# ipro7 register map
Vendor: intelpro; Series: BTBLE
CPU: ipro7, little endian
Registers are 32-bit, read-write, reset 0x0 unless marked. A register's access mark holds for its fields unless they carry their own. Offsets are from the block's base; [hi:lo] are bit positions; {n}, {i} and the like mark numbered series.

## GLB
Base 0x30000000
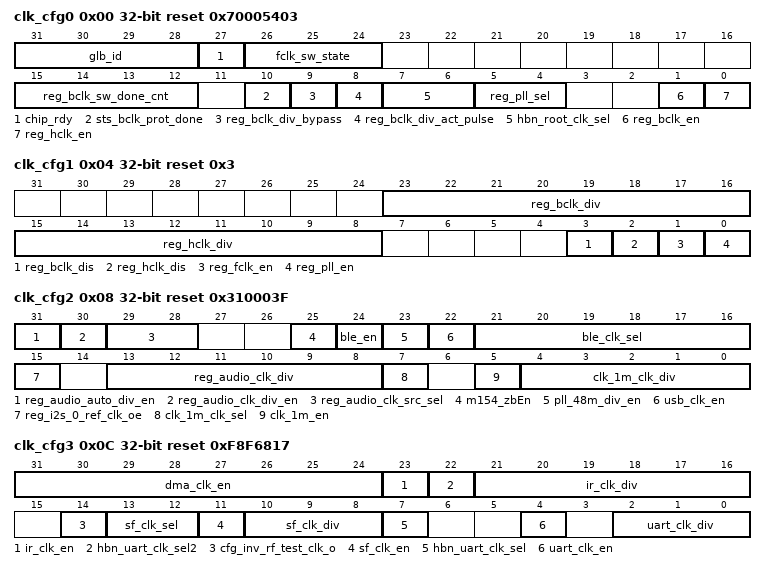
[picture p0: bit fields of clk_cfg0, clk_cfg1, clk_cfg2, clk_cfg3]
0x00 clk_cfg0 reset 0x70005403 (reset mask 0xFFFB3F)
  [31:28] glb_id ro
  [27] chip_rdy ro
  [26:24] fclk_sw_state ro
  [15:12] reg_bclk_sw_done_cnt — BCLK division protection done counter
  [10] sts_bclk_prot_done ro — clk protection done
  [9] reg_bclk_div_bypass — BCLK division protection bypass
  [8] reg_bclk_div_act_pulse wo — BCLK division protection activation
  [7:6] hbn_root_clk_sel ro — root clock selection from HBN (0: RC32M 1: XTAL 2/3: PLL others)
  [5:4] reg_pll_sel — pll clock selection 0: 25.6MHz 1: 42.66MHz 2: 64MHz 3: 128MHz
  [1] reg_bclk_en — bclk force on
  [0] reg_hclk_en — hclk force on
0x04 clk_cfg1 reset 0x3
  [23:16] reg_bclk_div — bclk divide from hclk
  [15:8] reg_hclk_div — hclk divide from root clock (clock source selected by hbn_root_clk_sel)
  [3] reg_bclk_dis — bclk force disable
  [2] reg_hclk_dis — hclk force disable
  [1] reg_fclk_en — fclk force on
  [0] reg_pll_en — pll clock enable for fclk
0x08 clk_cfg2 reset 0x310003F
  [31] reg_audio_auto_div_en — Audio auto div enable
  [30] reg_audio_clk_div_en — Audio clock div enable
  [29:28] reg_audio_clk_src_sel — 0 : 2.032MHz(128/63 from DLL), 1: 6.095MHz(128/21 from DLL), 2:pll_48m_clk, 3.clkpll_postdiv_outclk
  [25] m154_zbEn — mac154 zigbee clock enable
  [24] ble_en — ble clock enable
  [23] pll_48m_div_en — USB Clock div2 from 96MHz
  [22] usb_clk_en — USB Clock Enable
  [21:16] ble_clk_sel — HW reserved ; for ble to generate 1us/0.5us tick pulse
  [15] reg_i2s_0_ref_clk_oe — 0 : no output reference clock on I2S_0 ref_clock port ; 1: output reference clock on I2S_0 ref_clock port
  [13:8] reg_audio_clk_div — Audio clock div
  [7] clk_1m_clk_sel — KEY Clock Source Select. 0:xclk 1:f32k (PDS mode)
  [5] clk_1m_en — Clock 1M enable for kys/qdec
  [4:0] clk_1m_clk_div — KEY Clock Divider qdec_clk_sel/(N+1), default 1MHz
0x0C clk_cfg3 reset 0xF8F6817 (reset mask 0xFFBFFF7F)
  [31:24] dma_clk_en — DMA CH0~7 Clock Enable ; config all 0 if disable DMA
  [23] ir_clk_en — IR remote Clock Enable
  [22] hbn_uart_clk_sel2 ro — UART clock selection2 from HBN (0 : result of hbn_uart_clk_sel (fclk or dll_div2(64MHz)) 1: XCLK (XTAL or RC32M))
  [21:16] ir_clk_div — IR remote Clock Divider xclk(N+1)
  [14] cfg_inv_rf_test_clk_o — 1: invert rf_test_clk out, 0 : no change
  [13:12] sf_clk_sel — Flash Clock Select 0: xclk 1: dll_div2(64Mhz) 2: bclk (Default) 3: pll_80m_clk (80MHz)
  [11] sf_clk_en — Flash Clock Enable
  [10:8] sf_clk_div — Flash Clock Divider (Selected Flash Clock)/(N+1)
  [7] hbn_uart_clk_sel ro — UART clock selection from HBN (0:fclk 1:dll_div2(64MHz))
  [4] uart_clk_en — UART Clock Enable
  [2:0] uart_clk_div — UART Clock Divider hbn_uart_clk_sel/(N+1)
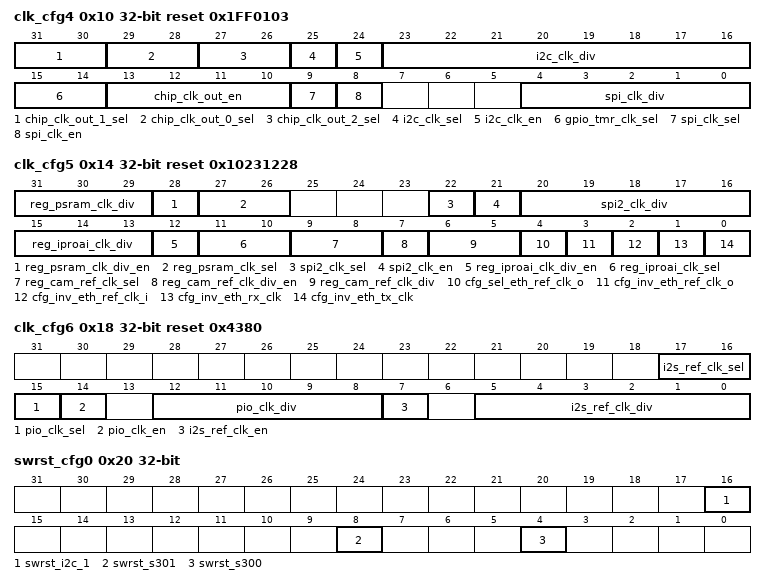
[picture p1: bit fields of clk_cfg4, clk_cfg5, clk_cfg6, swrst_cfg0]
0x10 clk_cfg4 reset 0x1FF0103
  [31:30] chip_clk_out_1_sel — clk_out_1 selection & clk_out_3 selection (0: no chip clock out, 1: f32k_clk, 2: ana_xtal_clk, 3: dig_xtal_clk)
  [29:28] chip_clk_out_0_sel — clk_out_0 selection & clk_out_2 selection (0: no chip clock out, 1: dll_div63, 2: dll_div21, 3: xclk)
  [27:26] chip_clk_out_2_sel — clk_out_1 selection & clk_out_3 selection (0: no chip clock out, 1: i2s_ref_clk, 2: pll_48m_clk, 3: clkpll_postdiv_outclk)
  [25] i2c_clk_sel — 0: BCLK, 1: XCLK
  [24] i2c_clk_en — I2C Master Clock Out Enable
  [23:16] i2c_clk_div — I2C Master Clock Out Divider (Freq_of_BCLK/(N+1))
  [15:14] gpio_tmr_clk_sel — select GPIO Clock Input From GPIO Function 0: 0: chip_clk_inout[0] 1: chip_clk_inout[1] 2: chip_clk_inout[2] 3: chip_clk_inout[3]
  [13:10] chip_clk_out_en — chip_clk_out enable for chip_clk_inout[3:0]
  [9] spi_clk_sel — 0: BCLK, 1: XCLK
  [8] spi_clk_en — SPI Clock Enable (Default : Enable)
  [4:0] spi_clk_div — SPI Clock Divider (BUS_CLK/(N+1)), default BUS_CLK/4
0x14 clk_cfg5 reset 0x10231228
  [31:29] reg_psram_clk_div — psram clock divide cnt
  [28] reg_psram_clk_div_en — psram clock enable
  [27:26] reg_psram_clk_sel — psram clock source selection 2'd0 - bclk 2'd1 - pll_160m_clk 2'd2 - pll_480m_clk 2'd3 - pll_192m_clk
  [22] spi2_clk_sel — 0: BCLK, 1: XCLK
  [21] spi2_clk_en — SPI Clock Enable (Default : Enable)
  [20:16] spi2_clk_div — SPI Clock Divider (BUS_CLK/(N+1)), default BUS_CLK/4
  [15:13] reg_iproai_clk_div — IPROAI clock divide cnt
  [12] reg_iproai_clk_div_en — IPROAI clock enable
  [11:10] reg_iproai_clk_sel — IPROAI clock source selection 2'd0 - bclk 2'd1 - pll_320m_clk 2'd2 - pll_240m_clk 2'd3 - dll_div5
  [9:8] reg_cam_ref_clk_sel — 2'd0 - xclk 2'd1 - dll_div3 2'd2 - pll_48m_clk 2'd3 - clkpll_postdiv_outclk
  [7] reg_cam_ref_clk_div_en — camera clock enable
  [6:5] reg_cam_ref_clk_div — camera clock divider cnt
  [4] cfg_sel_eth_ref_clk_o — 0 : select outside 50MHz RMII ref clock, 1: select inside 50MHz RMII ref clock
  [3] cfg_inv_eth_ref_clk_o — if cfg_sel_eth_ref_clk_o = 1, set this bit to 1 will invert the clock to RMII PHY
  [2] cfg_inv_eth_ref_clk_i — Invert clock to RMII REF_CLK
  [1] cfg_inv_eth_rx_clk — Invert clock to our RMII MAC RX
  [0] cfg_inv_eth_tx_clk — Invert clock to our RMII MAC TX
0x18 clk_cfg6 reset 0x4380
  [17:16] i2s_ref_clk_sel — 0 : 2.032MHz(128/63 from DLL), 1: 6.095MHz(128/21 from DLL), 2:pll_48m_clk, 3.clkpll_postdiv_outclk
  [15] pio_clk_sel — 0: PLL_160M_CLK, 1: XCLK
  [14] pio_clk_en — PIO Clock Enable (Default : Enable)
  [12:8] pio_clk_div — PIO Clock Divider (BUS_CLK/(N+1)), default BUS_CLK/4
  [7] i2s_ref_clk_en — I2S Clock Enable
  [5:0] i2s_ref_clk_div — I2S Clock Divider(N+1)
0x20 swrst_cfg0
  [16] swrst_i2c_1
  [8] swrst_s301 — BLE
  [4] swrst_s300 — M154
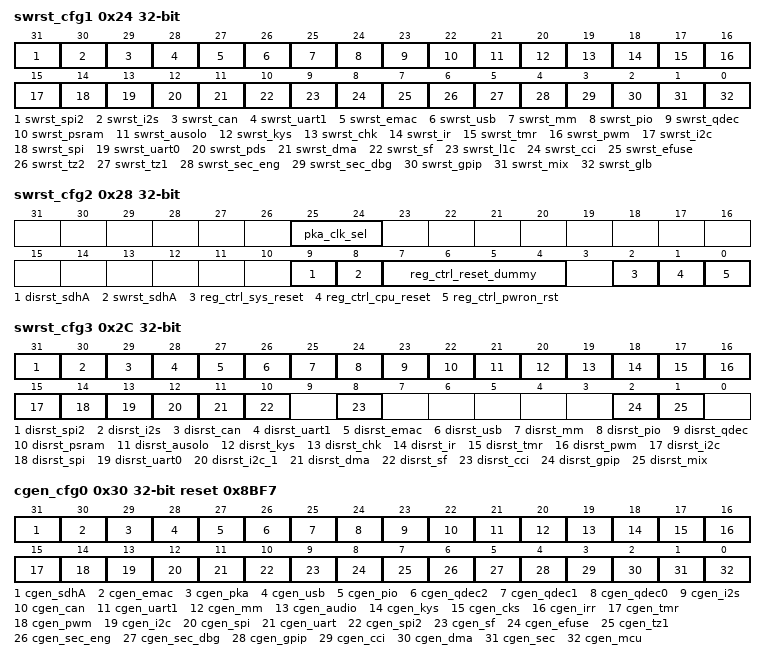
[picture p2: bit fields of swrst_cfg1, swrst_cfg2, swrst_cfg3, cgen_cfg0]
0x24 swrst_cfg1
  [31] swrst_spi2, [30] swrst_i2s, [29] swrst_can, [28] swrst_uart1, [27] swrst_emac, [26] swrst_usb, [25] swrst_mm, [24] swrst_pio, [23] swrst_qdec, [22] swrst_psram, [21] swrst_ausolo, [20] swrst_kys, [19] swrst_chk, [18] swrst_ir, [17] swrst_tmr, [16] swrst_pwm, [15] swrst_i2c, [14] swrst_spi, [13] swrst_uart0, [12] swrst_pds, [11] swrst_dma, [10] swrst_sf, [9] swrst_l1c, [8] swrst_cci, [7] swrst_efuse, [6] swrst_tz2, [5] swrst_tz1, [4] swrst_sec_eng, [3] swrst_sec_dbg, [2] swrst_gpip, [1] swrst_mix, [0] swrst_glb
0x28 swrst_cfg2
  [25:24] pka_clk_sel — 0:96Mhz, 1:128MHz, 2: 64MHz, 3: 42.6MHz
  [9] disrst_sdhA
  [8] swrst_sdhA
  [7:4] reg_ctrl_reset_dummy
  [2] reg_ctrl_sys_reset
  [1] reg_ctrl_cpu_reset
  [0] reg_ctrl_pwron_rst
0x2C swrst_cfg3
  [31] disrst_spi2, [30] disrst_i2s, [29] disrst_can, [28] disrst_uart1, [27] disrst_emac, [26] disrst_usb, [25] disrst_mm, [24] disrst_pio, [23] disrst_qdec, [22] disrst_psram, [21] disrst_ausolo, [20] disrst_kys, [19] disrst_chk, [18] disrst_ir, [17] disrst_tmr, [16] disrst_pwm, [15] disrst_i2c, [14] disrst_spi, [13] disrst_uart0, [12] disrst_i2c_1, [11] disrst_dma, [10] disrst_sf, [8] disrst_cci, [2] disrst_gpip, [1] disrst_mix
0x30 cgen_cfg0 reset 0x8BF7
  [31] cgen_sdhA, [30] cgen_emac, [29] cgen_pka, [28] cgen_usb, [27] cgen_pio, [26] cgen_qdec2, [25] cgen_qdec1, [24] cgen_qdec0, [23] cgen_i2s, [22] cgen_can, [21] cgen_uart1, [20] cgen_mm, [19] cgen_audio, [18] cgen_kys, [17] cgen_cks, [16] cgen_irr, [15] cgen_tmr, [14] cgen_pwm, [13] cgen_i2c, [12] cgen_spi, [11] cgen_uart, [10] cgen_spi2, [9] cgen_sf, [8] cgen_efuse, [7] cgen_tz1, [6] cgen_sec_eng, [5] cgen_sec_dbg, [4] cgen_gpip, [3] cgen_cci, [2] cgen_dma, [1] cgen_sec, [0] cgen_mcu
0x34 cgen_cfg1
  [14] cgen_i2c_1
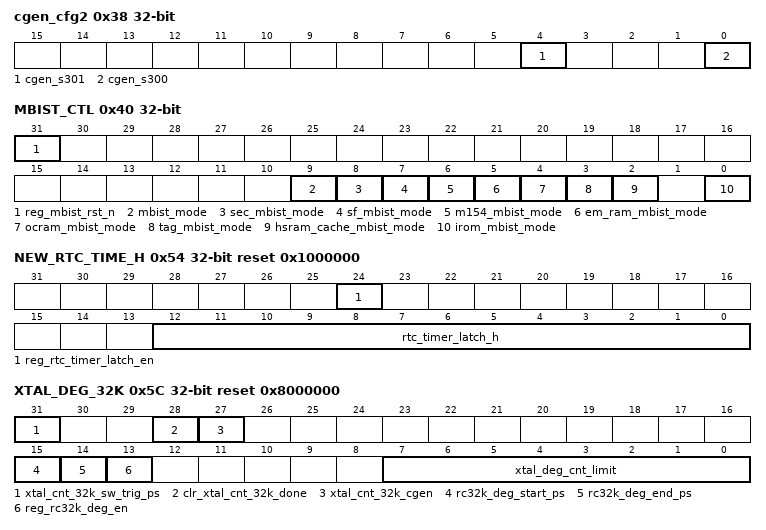
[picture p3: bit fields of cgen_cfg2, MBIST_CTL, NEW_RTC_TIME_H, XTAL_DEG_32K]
0x38 cgen_cfg2
  [4] cgen_s301 — ble clock enable (ble_en should also be 1)
  [0] cgen_s300 — mac154 zigbee clock enable (m154_zbEn should also be 1)
0x40 MBIST_CTL
  [31] reg_mbist_rst_n — MBIST Reset
  [9] mbist_mode — PIN MUX MBIST Mode
  [8] sec_mbist_mode
  [7] sf_mbist_mode
  [6] m154_mbist_mode
  [5] em_ram_mbist_mode — EM RAM MBIST Mode (16KB)
  [4] ocram_mbist_mode — OCRAM MBIST Mode (48KB)
  [3] tag_mbist_mode
  [2] hsram_cache_mbist_mode — HSRAM_CACHE MBIST Mode (16KB)
  [0] irom_mbist_mode
0x44 MBIST_STAT
0x50 NEW_RTC_TIME_L reset not defined
  [31:0] rtc_timer_latch_l ro — RTC time latched value bit 31:0
0x54 NEW_RTC_TIME_H reset 0x1000000 (reset mask 0xFFFFE000)
  [24] reg_rtc_timer_latch_en — Enable RTC Timer Latch, need to wait about 15us for 1st timer read, and no need to wait for next read
  [12:0] rtc_timer_latch_h ro — RTC time latched value bit 44:32
0x5C XTAL_DEG_32K reset 0x8000000
  [31] xtal_cnt_32k_sw_trig_ps wo — write one to set xtal_cnt_32k_process (0x4000E04C[29])
  [28] clr_xtal_cnt_32k_done wo — write one to clear xtal_cnt_32k_done (0x4000E04C[30])
  [27] xtal_cnt_32k_cgen
  [15] rc32k_deg_start_ps wo
  [14] rc32k_deg_end_ps wo
  [13] reg_rc32k_deg_en
  [7:0] xtal_deg_cnt_limit
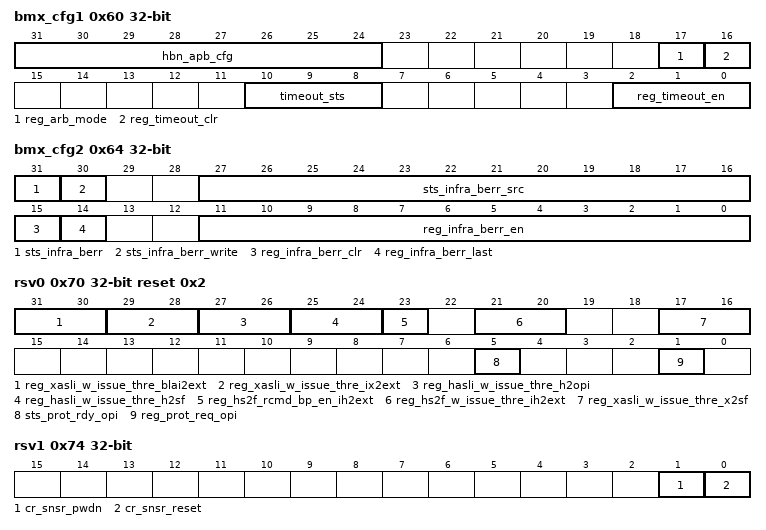
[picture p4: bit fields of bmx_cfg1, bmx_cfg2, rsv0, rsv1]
0x60 bmx_cfg1 (reset mask 0xFFFFF8FF)
  [31:24] hbn_apb_cfg — HW reserved. [7] hbn_hold_en [6:4] hbn_hold_cycle [3] hbn_setup_en [2:0] hbn_setup_cycle
  [17] reg_arb_mode — Bus arbiter: 0:fix, 2:round-robin, 3:random
  [16] reg_timeout_clr — Timeout Clear
  [10:8] timeout_sts ro — Bus timeout status
  [2:0] reg_timeout_en — Bus timeout enable: detect slave no reaponse in 1024 cycles
0x64 bmx_cfg2 (reset mask 0x3000FFFF)
  [31] sts_infra_berr ro — Bus addr error status
  [30] sts_infra_berr_write ro — Bus addr error write/read
  [27:16] sts_infra_berr_src ro — Bus addr error source
  [15] reg_infra_berr_clr — Bus addr error clear
  [14] reg_infra_berr_last — Bus addr error latch last addr
  [11:0] reg_infra_berr_en — Bus addr error monitor enable
0x68 bmx_err_addr reset not defined
  [31:0] sts_infra_berr_addr ro — Bus error addr (the first one)
0x6C bmx_cfg3
  [31:0] reg_frun_pclk — APB clock freerun
0x70 rsv0 reset 0x2 (reset mask 0xFFFFFFDF)
  [31:30] reg_xasli_w_issue_thre_blai2ext, [29:28] reg_xasli_w_issue_thre_ix2ext, [27:26] reg_hasli_w_issue_thre_h2opi, [25:24] reg_hasli_w_issue_thre_h2sf, [23] reg_hs2f_rcmd_bp_en_ih2ext, [21:20] reg_hs2f_w_issue_thre_ih2ext, [17:16] reg_xasli_w_issue_thre_x2sf, [5] sts_prot_rdy_opi ro, [1] reg_prot_req_opi
0x74 rsv1
  [1] cr_snsr_pwdn, [0] cr_snsr_reset
0x78 rsv2
0x7C rsv3 reset 0xFFFFFFFF
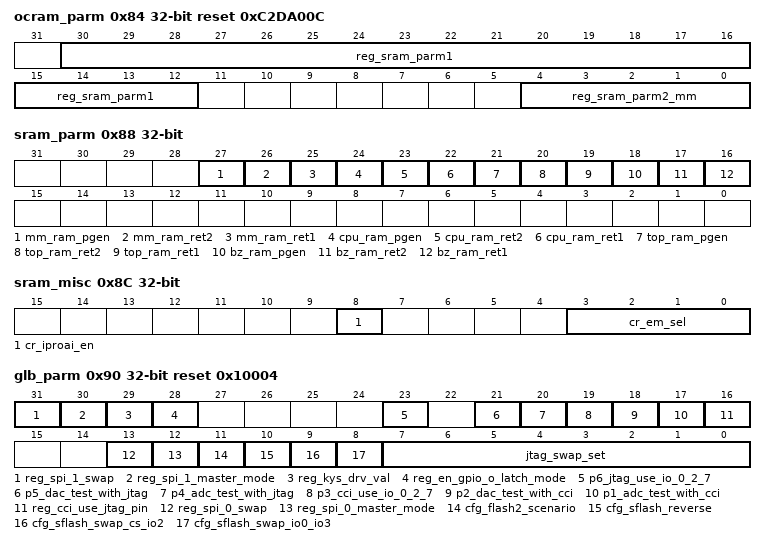
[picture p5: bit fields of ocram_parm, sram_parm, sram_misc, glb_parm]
0x84 ocram_parm reset 0xC2DA00C
  [30:12] reg_sram_parm1 — [30:29]=ram_bus[27:26]=WABLM_SRAM [28:26]=ram_bus[25:23]=EMA_SRAM [25:24]=ram_bus[22:21]=WABLM_RF [23:22]=ram_bus[20:19]=RAWLM [21]=ram_bus[18]=WABL [20]=ram_bus[17]=RAWL [19:18]=ram_bus[16:15]=EMAW [17:15]=ram_bus[14:12]=EMA_RF [14:12]=ram_bus[11:9]=EMA_ROM
  [4:0] reg_sram_parm2_mm — [5]=ram_bus[32]=DVSE [4:0]=ram_bus[31:28]=DVS
0x88 sram_parm
  [27] mm_ram_pgen, [26] mm_ram_ret2, [25] mm_ram_ret1, [24] cpu_ram_pgen, [23] cpu_ram_ret2, [22] cpu_ram_ret1, [21] top_ram_pgen, [20] top_ram_ret2, [19] top_ram_ret1, [18] bz_ram_pgen, [17] bz_ram_ret2, [16] bz_ram_ret1
0x8C sram_misc
  [8] cr_iproai_en — IPROAI SRAM enable 1'b0 - IPROAI disable / OCRAM - 256KB 1'b1 - IPROAI enable / OCRAM - 128KB
  [3:0] cr_em_sel — 4'b0000 - EM 0KB 4'b1000 - EM 16KB 4'b1100 - EM 32KB 4'b1110 - EM 48KB 4'b1111 - EM 64KB
0x90 glb_parm reset 0x10004
  [31] reg_spi_1_swap — 1: SWAP SPI1 MOSI with MISO ; 0 No SWAP
  [30] reg_spi_1_master_mode — 1 : SPI_1 Pad Act as Master, 0: SPI_1 Pad Act as Slave
  [29] reg_kys_drv_val — 1: Active Key Scan Column Drive, 0: Disable Key Scan Column Drive
  [28] reg_en_gpio_o_latch_mode — 1 : Enable GPIO_O Latch Mode
  [23] p6_jtag_use_io_0_2_7 — GPIO Scenario, set this bit will force GPI0/1/2/7 to JTAG Function
  [21] p5_dac_test_with_jtag — GPIO Scenario, set this bit will lead all GPIO enter DACTest Mode with JTAG
  [20] p4_adc_test_with_jtag — GPIO Scenario, set this bit will lead all GPIO enter ADCTest Mode with JTAG
  [19] p3_cci_use_io_0_2_7 — GPIO Scenario, set this bit will force GPIO0/1/2/7 to CCI Function
  [18] p2_dac_test_with_cci — GPIO Scenario, set this bit will lead all GPIO enter DACTest Mode with CCI
  [17] p1_adc_test_with_cci — GPIO Scenario, set this bit will lead all GPIO enter ADCTest Mode with CCI
  [16] reg_cci_use_jtag_pin — 1: CCI USE GPIO0~2 @ JTAG Function
  [13] reg_spi_0_swap — 1: SWAP SPI0 MOSI with MISO ; 0 No SWAP
  [12] reg_spi_0_master_mode — 1 : SPI_0 Pad Act as Master, 0: SPI_0 Pad Act as Slave
  [11] cfg_flash2_scenario — 0 : Flash GPIO Scenario Disabled, Flash GPIO Function Set by SW 1 : Flash GPIO Scenario Enable , Force GPIO23~28 to Flash2 Function
  [10] cfg_sflash_reverse — 1 : Embedded Flash Interface Reverse 0 : no revserse
  [9] cfg_sflash_swap_cs_io2 — Embedded Flash SWAP 1 : SWAP SFLASH CS with IO2 : No SWAP SFLASH CS With IO2
  [8] cfg_sflash_swap_io0_io3 — 1 : SWAP SFLASH IO3 with IO 0 : No SWAP SFLASH IO3 With IO0
  [7:0] jtag_swap_set — [0] : SWAP JTAG GPIO SET0 (GPIO0~GPIO3) (1: E21_TMS/E21_TDI/E21_TCK/E21_TDO -> E21_TCK/E21_TDO/E21_TMS/E21_TDI) [1] : SWAP JTAG GPIO SET0 (GPIO4~GPIO7) (1: E21_TMS/E21_TDI/E21_TCK/E21_TDO -> E21_TCK/E21_TDO/E21_TMS/E21_TDI) [2] : SWAP JTAG GPIO SET0 (GPIO8~GPIO11) (1: E21_TMS/E21_TDI/E21_TCK/E21_TDO -> E21_TCK/E21_TDO/E21_TMS/E21_TDI) [3] : SWAP JTAG GPIO SET0 (GPIO12~GPIO15) (1: E21_TMS/E21_TDI/E21_TCK/E21_TDO -> E21_TCK/E21_TDO/E21_TMS/E21_TDI) [4] : SWAP JTAG GPIO SET0 (GPIO16~GPIO19) (1: E21_TMS/E21_TDI/E21_TCK/E21_TDO -> E21_TCK/E21_TDO/E21_TMS/E21_TDI) [5] : SWAP JTAG GPIO SET0 (GPIO20~GPIO23) (1: E21_TMS/E21_TDI/E21_TCK/E21_TDO -> E21_TCK/E21_TDO/E21_TMS/E21_TDI) [6] : SWAP JTAG GPIO SET0 (GPIO24~GPIO27) (1: E21_TMS/E21_TDI/E21_TCK/E21_TDO -> E21_TCK/E21_TDO/E21_TMS/E21_TDI) [7] : SWAP JTAG GPIO SET0 (GPIO28~GPIO31) (1: E21_TMS/E21_TDI/E21_TCK/E21_TDO -> E21_TCK/E21_TDO/E21_TMS/E21_TDI)
0x94 PDM_CLK_CTRL
0x98 GPIO_USE_PSRAM__IO
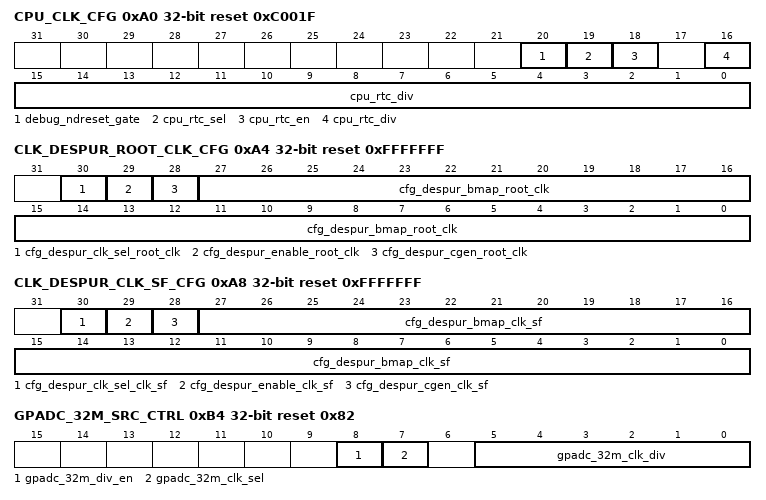
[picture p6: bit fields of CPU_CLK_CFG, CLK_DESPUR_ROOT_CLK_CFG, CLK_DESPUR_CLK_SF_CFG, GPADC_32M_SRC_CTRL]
0xA0 CPU_CLK_CFG reset 0xC001F
  [20] debug_ndreset_gate — Gating CPU debug reset
  [19] cpu_rtc_sel — 0: Divide from fclk 1: 32KHz
  [18] cpu_rtc_en — CPU RTC clock enable
  [16:0] cpu_rtc_div — CPU RTC clock = (e21_rtc_sel) / (e21_rtc_div+1)
0xA4 CLK_DESPUR_ROOT_CLK_CFG reset 0xFFFFFFF
  [30] cfg_despur_clk_sel_root_clk, [29] cfg_despur_enable_root_clk, [28] cfg_despur_cgen_root_clk, [27:0] cfg_despur_bmap_root_clk
0xA8 CLK_DESPUR_CLK_SF_CFG reset 0xFFFFFFF
  [30] cfg_despur_clk_sel_clk_sf, [29] cfg_despur_enable_clk_sf, [28] cfg_despur_cgen_clk_sf, [27:0] cfg_despur_bmap_clk_sf
0xAC WIFI_BT_COEX_CTRL
0xB4 GPADC_32M_SRC_CTRL reset 0x82
  [8] gpadc_32m_div_en — GPADC 32M Clock Dvider Enable
  [7] gpadc_32m_clk_sel — GPADC Clock Source Select. 0: f32k_clk, 1: xclk
  [5:0] gpadc_32m_clk_div — GPADC 32M Clock Divider (gpadc clock)/(N+1)
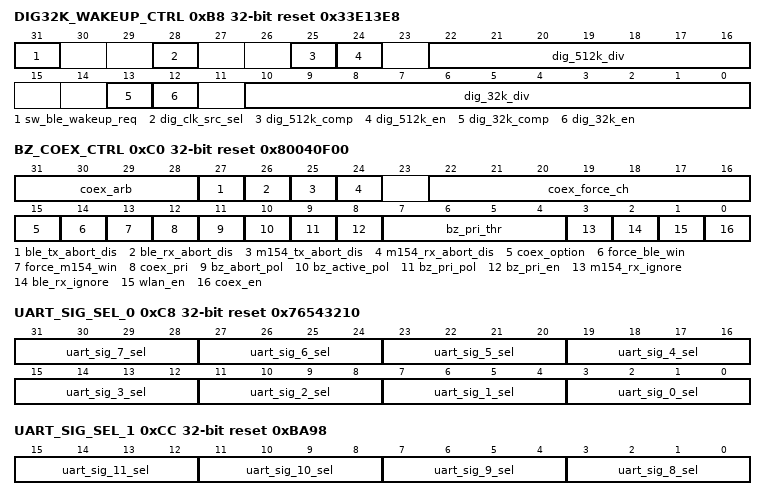
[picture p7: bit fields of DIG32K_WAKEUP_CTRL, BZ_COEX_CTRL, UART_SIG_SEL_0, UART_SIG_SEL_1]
0xB8 DIG32K_WAKEUP_CTRL reset 0x33E13E8
  [31] sw_ble_wakeup_req — 1: sw wakeup ble even ble HW in infinite sleep
  [28] dig_clk_src_sel — 0:XTAL32M 1:RC32M
  [25] dig_512k_comp — Compensation => Duty of dig_512k_out = N : N+1
  [24] dig_512k_en — Enable dig_512k_out
  [22:16] dig_512k_div — (PLL 32MHz or xclk) / dig_512k_div Ex: Set 46 for 24MHz ; Set 62 for 32MHz ; Set 75 for 38.4MHz ; Set 78 for 40MHz
  [13] dig_32k_comp — Compensation => Duty of dig_32k_out = dig_32k_div : (dig_32k_div+1)
  [12] dig_32k_en — Enable dig_32k_out
  [10:0] dig_32k_div — (PLL 32MHz or xclk) / dig_32k_div Ex: Set 750 for 24MHz ; Set 1000 for 32MHz ; Set 1200 for 38.4MHz ; Set 1250 for 40MHz
0xC0 BZ_COEX_CTRL reset 0x80040F00 (reset mask 0xFFFFFFF)
  [31:28] coex_arb ro — [0]: M154, [1]: BLE, [2]:External, [3]: IDLE, one-hot coding.
  [27] ble_tx_abort_dis
  [26] ble_rx_abort_dis
  [25] m154_tx_abort_dis
  [24] m154_rx_abort_dis
  [22:16] coex_force_ch — Force Channel (0-78)
  [15] coex_option — 0:immediate, 1:wait
  [14] force_ble_win
  [13] force_m154_win
  [12] coex_pri
  [11] bz_abort_pol — Abort pin polarity
  [10] bz_active_pol — Active pin polarity
  [9] bz_pri_pol — Priority pin polarity
  [8] bz_pri_en — Enable function of bz_pri pin. Otherwise, bz_pri pin is equal to bz_active pin.
  [7:4] bz_pri_thr — Coex priority threshold.
  [3] m154_rx_ignore — ignore m154 rx
  [2] ble_rx_ignore — ignore ble rx
  [1] wlan_en — wlan is enabled
  [0] coex_en — Coex enable (either 2 of wlan/ble/m154 enable)
0xC8 UART_SIG_SEL_0 reset 0x76543210
  [4n+3:4n] uart_sig_{n}_sel (n=0..7) — UART Signal{n} Select : 0 : UART0_RTS 1 : UART0_CTS 2 : UART0_TXD 3 : UART0_RXD 4 : UART1_RTS 5 : UART1_CTS 6 : UART1_TXD 7 : UART1_RXD
0xCC UART_SIG_SEL_1 reset 0xBA98
  [4n-29:4n-32] uart_sig_{n}_sel (n=8..11)
0xD0 DBG_SEL_LL
  [31:0] reg_dbg_ll_ctrl — [31:2] Debug Set : 1~30 Debug Signal Set selection, and Only one bit can be asserted for selection [1:0] Debug Selection : 00 : select [7:0] of debug set signal 01 : select [15:8] of debug set signal 10 : select [23:16] of debug set signal 11 : select [31:24] of debug set signal
0xD4 DBG_SEL_LH
  [31:0] reg_dbg_lh_ctrl — [31:2] Debug Set : 1~30 Debug Signal Set selection, and Only one bit can be asserted for selection [1:0] Debug Selection : 00 : select [7:0] of debug set signal 01 : select [15:8] of debug set signal 10 : select [23:16] of debug set signal 11 : select [31:24] of debug set signal
0xD8 DBG_SEL_HL
  [31:0] reg_dbg_hl_ctrl — [31:2] Debug Set : 1~30 Debug Signal Set selection, and Only one bit can be asserted for selection [1:0] Debug Selection : 00 : select [7:0] of debug set signal 01 : select [15:8] of debug set signal 10 : select [23:16] of debug set signal 11 : select [31:24] of debug set signal
0xDC DBG_SEL_HH
  [31:0] reg_dbg_hh_ctrl — [31:2] Debug Set : 1~30 Debug Signal Set selection, and Only one bit can be asserted for selection [1:0] Debug Selection : 00 : select [7:0] of debug set signal 01 : select [15:8] of debug set signal 10 : select [23:16] of debug set signal 11 : select [31:24] of debug set signal
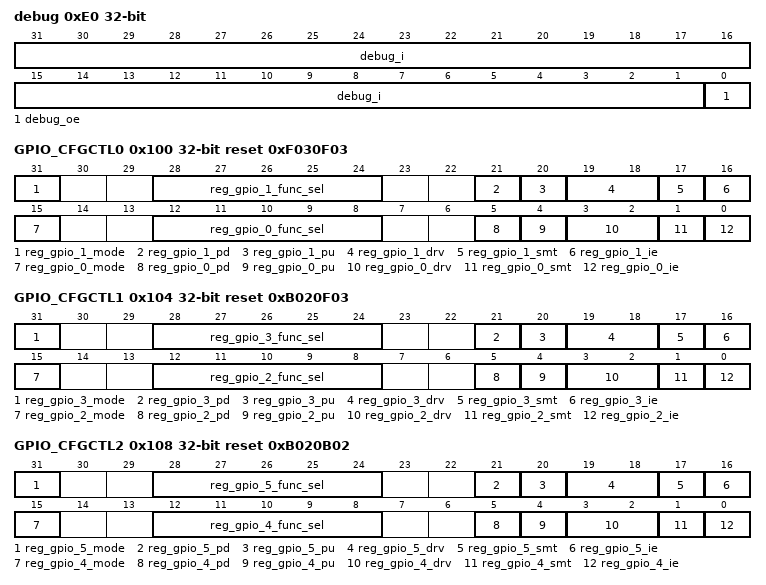
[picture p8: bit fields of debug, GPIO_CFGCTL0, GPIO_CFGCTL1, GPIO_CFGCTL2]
0xE0 debug (reset mask 0x1)
  [31:1] debug_i ro, [0] debug_oe
0x100 GPIO_CFGCTL0 reset 0xF030F03
  [31] reg_gpio_1_mode — When GPIO Function Selected to SWGPIO and reg_en_gpio_o_latch_mode =1 0 (Output Value Mode): GPIO Output by reg_gpio_x_o Value 1 (Set/Celar Mode ) :GPIO Output set by reg_gpio_x_set and clear by reg_gpio_x_clr
  [28:24] reg_gpio_1_func_sel — GPIO Function Select (Default : CCI)
  [21] reg_gpio_1_pd — GPIO Pull Down Control
  [20] reg_gpio_1_pu — GPIO Pull Up Control
  [19:18] reg_gpio_1_drv — GPIO Driving Control
  [17] reg_gpio_1_smt — GPIO SMT Control
  [16] reg_gpio_1_ie — GPIO Input Enable
  [15] reg_gpio_0_mode — When GPIO Function Selected to SWGPIO and reg_en_gpio_o_latch_mode =1 0 (Output Value Mode): GPIO Output by reg_gpio_x_o Value 1 (Set/Celar Mode ) :GPIO Output set by reg_gpio_x_set and clear by reg_gpio_x_clr
  [12:8] reg_gpio_0_func_sel — GPIO Function Select (Default : CCI)
  [5] reg_gpio_0_pd — GPIO Pull Down Control
  [4] reg_gpio_0_pu — GPIO Pull Up Control
  [3:2] reg_gpio_0_drv — GPIO Driving Control
  [1] reg_gpio_0_smt — GPIO SMT Control
  [0] reg_gpio_0_ie — GPIO Input Enable
0x104 GPIO_CFGCTL1 reset 0xB020F03
  [31] reg_gpio_3_mode — When GPIO Function Selected to SWGPIO and reg_en_gpio_o_latch_mode =1 0 (Output Value Mode): GPIO Output by reg_gpio_x_o Value 1 (Set/Celar Mode ) :GPIO Output set by reg_gpio_x_set and clear by reg_gpio_x_clr
  [28:24] reg_gpio_3_func_sel — GPIO Function Select (Default : SWGPIO)
  [21] reg_gpio_3_pd — GPIO Pull Down Control
  [20] reg_gpio_3_pu — GPIO Pull Up Control
  [19:18] reg_gpio_3_drv — GPIO Driving Control
  [17] reg_gpio_3_smt — GPIO SMT Control
  [16] reg_gpio_3_ie — GPIO Input Enable
  [15] reg_gpio_2_mode — When GPIO Function Selected to SWGPIO and reg_en_gpio_o_latch_mode =1 0 (Output Value Mode): GPIO Output by reg_gpio_x_o Value 1 (Set/Celar Mode ) :GPIO Output set by reg_gpio_x_set and clear by reg_gpio_x_clr
  [12:8] reg_gpio_2_func_sel — GPIO Function Select (Default : CCI)
  [5] reg_gpio_2_pd — GPIO Pull Down Control
  [4] reg_gpio_2_pu — GPIO Pull Up Control
  [3:2] reg_gpio_2_drv — GPIO Driving Control
  [1] reg_gpio_2_smt — GPIO SMT Control
  [0] reg_gpio_2_ie — GPIO Input Enable
0x108 GPIO_CFGCTL2 reset 0xB020B02
  [31] reg_gpio_5_mode — When GPIO Function Selected to SWGPIO and reg_en_gpio_o_latch_mode =1 0 (Output Value Mode): GPIO Output by reg_gpio_x_o Value 1 (Set/Celar Mode ) :GPIO Output set by reg_gpio_x_set and clear by reg_gpio_x_clr
  [28:24] reg_gpio_5_func_sel — GPIO Function Select (Default : SWGPIO)
  [21] reg_gpio_5_pd — GPIO Pull Down Control
  [20] reg_gpio_5_pu — GPIO Pull Up Control
  [19:18] reg_gpio_5_drv — GPIO Driving Control
  [17] reg_gpio_5_smt — GPIO SMT Control
  [16] reg_gpio_5_ie — GPIO Input Enable
  [15] reg_gpio_4_mode — When GPIO Function Selected to SWGPIO and reg_en_gpio_o_latch_mode =1 0 (Output Value Mode): GPIO Output by reg_gpio_x_o Value 1 (Set/Celar Mode ) :GPIO Output set by reg_gpio_x_set and clear by reg_gpio_x_clr
  [12:8] reg_gpio_4_func_sel — GPIO Function Select (Default : SWGPIO)
  [5] reg_gpio_4_pd — GPIO Pull Down Control
  [4] reg_gpio_4_pu — GPIO Pull Up Control
  [3:2] reg_gpio_4_drv — GPIO Driving Control
  [1] reg_gpio_4_smt — GPIO SMT Control
  [0] reg_gpio_4_ie — GPIO Input Enable
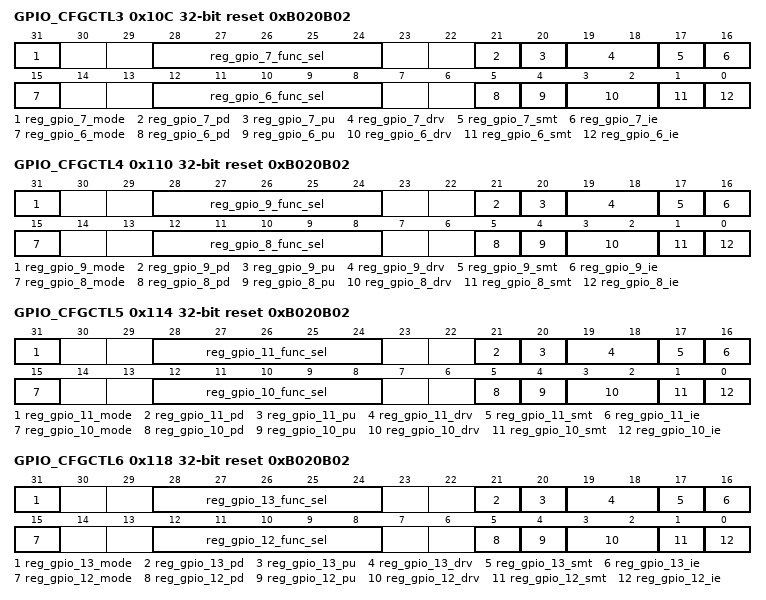
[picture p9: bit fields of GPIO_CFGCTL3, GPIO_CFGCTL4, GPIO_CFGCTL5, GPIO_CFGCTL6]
0x10C GPIO_CFGCTL3 reset 0xB020B02
  [31] reg_gpio_7_mode — When GPIO Function Selected to SWGPIO and reg_en_gpio_o_latch_mode =1 0 (Output Value Mode): GPIO Output by reg_gpio_x_o Value 1 (Set/Celar Mode ) :GPIO Output set by reg_gpio_x_set and clear by reg_gpio_x_clr
  [28:24] reg_gpio_7_func_sel — GPIO Function Select (Default : SWGPIO)
  [21] reg_gpio_7_pd — GPIO Pull Down Control
  [20] reg_gpio_7_pu — GPIO Pull Up Control
  [19:18] reg_gpio_7_drv — GPIO Driving Control
  [17] reg_gpio_7_smt — GPIO SMT Control
  [16] reg_gpio_7_ie — GPIO Input Enable
  [15] reg_gpio_6_mode — When GPIO Function Selected to SWGPIO and reg_en_gpio_o_latch_mode =1 0 (Output Value Mode): GPIO Output by reg_gpio_x_o Value 1 (Set/Celar Mode ) :GPIO Output set by reg_gpio_x_set and clear by reg_gpio_x_clr
  [12:8] reg_gpio_6_func_sel — GPIO Function Select (Default : SWGPIO )
  [5] reg_gpio_6_pd — GPIO Pull Down Control
  [4] reg_gpio_6_pu — GPIO Pull Up Control
  [3:2] reg_gpio_6_drv — GPIO Driving Control
  [1] reg_gpio_6_smt — GPIO SMT Control
  [0] reg_gpio_6_ie — GPIO Input Enable
0x110 GPIO_CFGCTL4 reset 0xB020B02
  [31] reg_gpio_9_mode — When GPIO Function Selected to SWGPIO and reg_en_gpio_o_latch_mode =1 0 (Output Value Mode): GPIO Output by reg_gpio_x_o Value 1 (Set/Celar Mode ) :GPIO Output set by reg_gpio_x_set and clear by reg_gpio_x_clr
  [28:24] reg_gpio_9_func_sel — GPIO Function Select (Default : SWGPIO )
  [21] reg_gpio_9_pd — GPIO Pull Down Control (Use this bit if reg_en_hw_pu_pd := 0 (0x4000F014[16])
  [20] reg_gpio_9_pu — GPIO Pull Up Control (Use this bit if reg_en_hw_pu_pd := 0 (0x4000F014[16])
  [19:18] reg_gpio_9_drv — GPIO Driving Control
  [17] reg_gpio_9_smt — GPIO SMT Control(Useless, IE depend on reg_aon_pad_ie_smt[0] : 0x4000F014[8])
  [16] reg_gpio_9_ie — GPIO Input Enable (Useless, IE depend on reg_aon_pad_ie_smt[0] : 0x4000F014[8])
  [15] reg_gpio_8_mode — When GPIO Function Selected to SWGPIO and reg_en_gpio_o_latch_mode =1 0 (Output Value Mode): GPIO Output by reg_gpio_x_o Value 1 (Set/Celar Mode ) :GPIO Output set by reg_gpio_x_set and clear by reg_gpio_x_clr
  [12:8] reg_gpio_8_func_sel — GPIO Function Select (Default : SWGPIO )
  [5] reg_gpio_8_pd — GPIO Pull Down Control
  [4] reg_gpio_8_pu — GPIO Pull Up Control
  [3:2] reg_gpio_8_drv — GPIO Driving Control
  [1] reg_gpio_8_smt — GPIO SMT Control
  [0] reg_gpio_8_ie — GPIO Input Enable
0x114 GPIO_CFGCTL5 reset 0xB020B02
  [31] reg_gpio_11_mode — When GPIO Function Selected to SWGPIO and reg_en_gpio_o_latch_mode =1 0 (Output Value Mode): GPIO Output by reg_gpio_x_o Value 1 (Set/Celar Mode ) :GPIO Output set by reg_gpio_x_set and clear by reg_gpio_x_clr
  [28:24] reg_gpio_11_func_sel — GPIO Function Select (Default : SWGPIO )
  [21] reg_gpio_11_pd — GPIO Pull Down Control
  [20] reg_gpio_11_pu — GPIO Pull Up Control
  [19:18] reg_gpio_11_drv — GPIO Driving Control
  [17] reg_gpio_11_smt — GPIO SMT Control(Useless, IE depend on reg_aon_pad_ie_smt[2] : 0x4000F014[10])
  [16] reg_gpio_11_ie — GPIO Input Enable (Useless, IE depend on reg_aon_pad_ie_smt[2] : 0x4000F014[10])
  [15] reg_gpio_10_mode — When GPIO Function Selected to SWGPIO and reg_en_gpio_o_latch_mode =1 0 (Output Value Mode): GPIO Output by reg_gpio_x_o Value 1 (Set/Celar Mode ) :GPIO Output set by reg_gpio_x_set and clear by reg_gpio_x_clr
  [12:8] reg_gpio_10_func_sel — GPIO Function Select (Default : SWGPIO )
  [5] reg_gpio_10_pd — GPIO Pull Down Control
  [4] reg_gpio_10_pu — GPIO Pull Up Control
  [3:2] reg_gpio_10_drv — GPIO Driving Control
  [1] reg_gpio_10_smt — GPIO SMT Control(Useless, IE depend on reg_aon_pad_ie_smt[1] : 0x4000F014[9])
  [0] reg_gpio_10_ie — GPIO Input Enable (Useless, IE depend on reg_aon_pad_ie_smt[1] : 0x4000F014[9])
0x118 GPIO_CFGCTL6 reset 0xB020B02
  [31] reg_gpio_13_mode — When GPIO Function Selected to SWGPIO and reg_en_gpio_o_latch_mode =1 0 (Output Value Mode): GPIO Output by reg_gpio_x_o Value 1 (Set/Celar Mode ) :GPIO Output set by reg_gpio_x_set and clear by reg_gpio_x_clr
  [28:24] reg_gpio_13_func_sel — GPIO Function Select (Default : SWGPIO )
  [21] reg_gpio_13_pd — GPIO Pull Down Control
  [20] reg_gpio_13_pu — GPIO Pull Up Control
  [19:18] reg_gpio_13_drv — GPIO Driving Control
  [17] reg_gpio_13_smt — GPIO SMT Control(Useless, IE depend on reg_aon_pad_ie_smt[4] : 0x4000F014[12])
  [16] reg_gpio_13_ie — GPIO Input Enable (Useless, IE depend on reg_aon_pad_ie_smt[4] : 0x4000F014[12])
  [15] reg_gpio_12_mode — When GPIO Function Selected to SWGPIO and reg_en_gpio_o_latch_mode =1 0 (Output Value Mode): GPIO Output by reg_gpio_x_o Value 1 (Set/Celar Mode ) :GPIO Output set by reg_gpio_x_set and clear by reg_gpio_x_clr
  [12:8] reg_gpio_12_func_sel — GPIO Function Select (Default : SWGPIO )
  [5] reg_gpio_12_pd — GPIO Pull Down Control
  [4] reg_gpio_12_pu — GPIO Pull Up Control
  [3:2] reg_gpio_12_drv — GPIO Driving Control
  [1] reg_gpio_12_smt — GPIO SMT Control(Useless, IE depend on reg_aon_pad_ie_smt[3] : 0x4000F014[11])
  [0] reg_gpio_12_ie — GPIO Input Enable (Useless, IE depend on reg_aon_pad_ie_smt[3] : 0x4000F014[11])
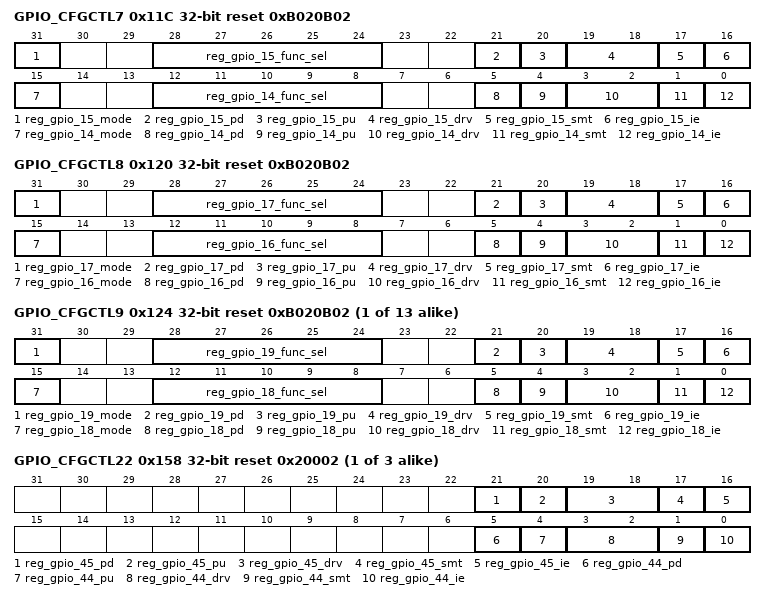
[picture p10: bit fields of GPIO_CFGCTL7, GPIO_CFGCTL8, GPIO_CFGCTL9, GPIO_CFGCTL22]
0x11C GPIO_CFGCTL7 reset 0xB020B02
  [31] reg_gpio_15_mode — When GPIO Function Selected to SWGPIO and reg_en_gpio_o_latch_mode =1 0 (Output Value Mode): GPIO Output by reg_gpio_x_o Value 1 (Set/Celar Mode ) :GPIO Output set by reg_gpio_x_set and clear by reg_gpio_x_clr
  [28:24] reg_gpio_15_func_sel — GPIO Function Select (Default : SWGPIO )
  [21] reg_gpio_15_pd — GPIO Pull Down Control
  [20] reg_gpio_15_pu — GPIO Pull Up Control
  [19:18] reg_gpio_15_drv — GPIO Driving Control
  [17] reg_gpio_15_smt — GPIO SMT Control
  [16] reg_gpio_15_ie — GPIO Input Enable
  [15] reg_gpio_14_mode — When GPIO Function Selected to SWGPIO and reg_en_gpio_o_latch_mode =1 0 (Output Value Mode): GPIO Output by reg_gpio_x_o Value 1 (Set/Celar Mode ) :GPIO Output set by reg_gpio_x_set and clear by reg_gpio_x_clr
  [12:8] reg_gpio_14_func_sel — GPIO Function Select (Default : SWGPIO )
  [5] reg_gpio_14_pd — GPIO Pull Down Control
  [4] reg_gpio_14_pu — GPIO Pull Up Control
  [3:2] reg_gpio_14_drv — GPIO Driving Control
  [1] reg_gpio_14_smt — GPIO SMT Control
  [0] reg_gpio_14_ie — GPIO Input Enable
0x120 GPIO_CFGCTL8 reset 0xB020B02
  [31] reg_gpio_17_mode — When GPIO Function Selected to SWGPIO and reg_en_gpio_o_latch_mode =1 0 (Output Value Mode): GPIO Output by reg_gpio_x_o Value 1 (Set/Celar Mode ) :GPIO Output set by reg_gpio_x_set and clear by reg_gpio_x_clr
  [28:24] reg_gpio_17_func_sel — GPIO Function Select (Default : SWGPIO )
  [21] reg_gpio_17_pd — GPIO Pull Down Control (Use this bit if reg_en_hw_pu_pd := 0 (0x4000F014[16])
  [20] reg_gpio_17_pu — GPIO Pull Up Control (Use this bit if reg_en_hw_pu_pd := 0 (0x4000F014[16])
  [19:18] reg_gpio_17_drv — GPIO Driving Control
  [17] reg_gpio_17_smt — GPIO SMT Control
  [16] reg_gpio_17_ie — GPIO Input Enable
  [15] reg_gpio_16_mode — When GPIO Function Selected to SWGPIO and reg_en_gpio_o_latch_mode =1 0 (Output Value Mode): GPIO Output by reg_gpio_x_o Value 1 (Set/Celar Mode ) :GPIO Output set by reg_gpio_x_set and clear by reg_gpio_x_clr
  [12:8] reg_gpio_16_func_sel — GPIO Function Select (Default : SWGPIO )
  [5] reg_gpio_16_pd — GPIO Pull Down Control
  [4] reg_gpio_16_pu — GPIO Pull Up Control
  [3:2] reg_gpio_16_drv — GPIO Driving Control
  [1] reg_gpio_16_smt — GPIO SMT Control
  [0] reg_gpio_16_ie — GPIO Input Enable
{0x100+4i} GPIO_CFGCTL{i} reset 0xB020B02 (i=9..21)
  [31] reg_gpio_{2i+1}_mode — When GPIO Function Selected to SWGPIO and reg_en_gpio_o_latch_mode =1 0 (Output Value Mode): GPIO Output by reg_gpio_x_o Value 1 (Set/Celar Mode ) :GPIO Output set by reg_gpio_x_set and clear by reg_gpio_x_clr
  [28:24] reg_gpio_{2i+1}_func_sel — GPIO Function Select (Default : SWGPIO )
  [21] reg_gpio_{2i+1}_pd — GPIO Pull Down Control
  [20] reg_gpio_{2i+1}_pu — GPIO Pull Up Control
  [19:18] reg_gpio_{2i+1}_drv — GPIO Driving Control
  [17] reg_gpio_{2i+1}_smt — GPIO SMT Control
  [16] reg_gpio_{2i+1}_ie — GPIO Input Enable
  [15] reg_gpio_{2i}_mode — When GPIO Function Selected to SWGPIO and reg_en_gpio_o_latch_mode =1 0 (Output Value Mode): GPIO Output by reg_gpio_x_o Value 1 (Set/Celar Mode ) :GPIO Output set by reg_gpio_x_set and clear by reg_gpio_x_clr
  [12:8] reg_gpio_{2i}_func_sel — GPIO Function Select (Default : SWGPIO )
  [5] reg_gpio_{2i}_pd — GPIO Pull Down Control
  [4] reg_gpio_{2i}_pu — GPIO Pull Up Control
  [3:2] reg_gpio_{2i}_drv — GPIO Driving Control
  [1] reg_gpio_{2i}_smt — GPIO SMT Control
  [0] reg_gpio_{2i}_ie — GPIO Input Enable
{0x100+4i} GPIO_CFGCTL{i} reset 0x20002 (i=22..24)
  [21] reg_gpio_{2i+1}_pd — GPIO Pull Down Control
  [20] reg_gpio_{2i+1}_pu — GPIO Pull Up Control
  [19:18] reg_gpio_{2i+1}_drv — GPIO Driving Control
  [17] reg_gpio_{2i+1}_smt — GPIO SMT Control
  [16] reg_gpio_{2i+1}_ie — GPIO Input Enable
  [5] reg_gpio_{2i}_pd — GPIO Pull Down Control
  [4] reg_gpio_{2i}_pu — GPIO Pull Up Control
  [3:2] reg_gpio_{2i}_drv — GPIO Driving Control
  [1] reg_gpio_{2i}_smt — GPIO SMT Control
  [0] reg_gpio_{2i}_ie — GPIO Input Enable
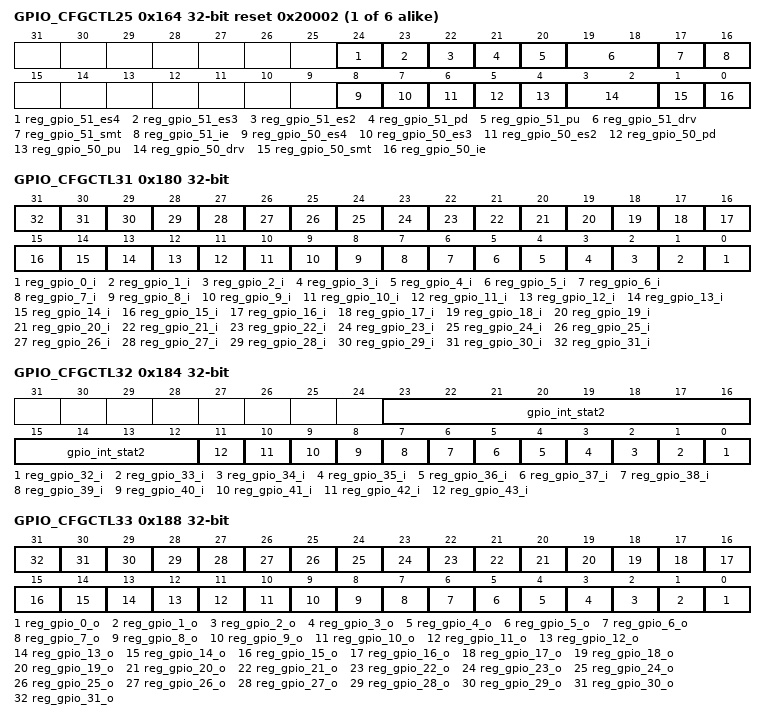
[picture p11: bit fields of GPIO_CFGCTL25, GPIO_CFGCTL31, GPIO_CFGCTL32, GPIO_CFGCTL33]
{0x100+4i} GPIO_CFGCTL{i} reset 0x20002 (i=25..30)
  [24] reg_gpio_{2i+1}_es4 — GPIO Driving Control
  [23] reg_gpio_{2i+1}_es3 — GPIO Driving Control
  [22] reg_gpio_{2i+1}_es2 — GPIO Driving Control
  [21] reg_gpio_{2i+1}_pd — GPIO Pull Down Control
  [20] reg_gpio_{2i+1}_pu — GPIO Pull Up Control
  [19:18] reg_gpio_{2i+1}_drv — GPIO Driving Control
  [17] reg_gpio_{2i+1}_smt — GPIO SMT Control
  [16] reg_gpio_{2i+1}_ie — GPIO Input Enable
  [8] reg_gpio_{2i}_es4 — GPIO Driving Control
  [7] reg_gpio_{2i}_es3 — GPIO Driving Control
  [6] reg_gpio_{2i}_es2 — GPIO Driving Control
  [5] reg_gpio_{2i}_pd — GPIO Pull Down Control
  [4] reg_gpio_{2i}_pu — GPIO Pull Up Control
  [3:2] reg_gpio_{2i}_drv — GPIO Driving Control
  [1] reg_gpio_{2i}_smt — GPIO SMT Control
  [0] reg_gpio_{2i}_ie — GPIO Input Enable
0x180 GPIO_CFGCTL31 reset not defined
  [n] reg_gpio_{n}_i ro (n=0..31) — Register Controlled GPIO Input value
0x184 GPIO_CFGCTL32 (reset mask 0xFF000000)
  [23:12] gpio_int_stat2 ro
  [n-32] reg_gpio_{n}_i ro (n=32..43) — Register Controlled GPIO Input value
0x188 GPIO_CFGCTL33
  [n] reg_gpio_{n}_o (n=0..31) — Register Controlled GPIO Output Value
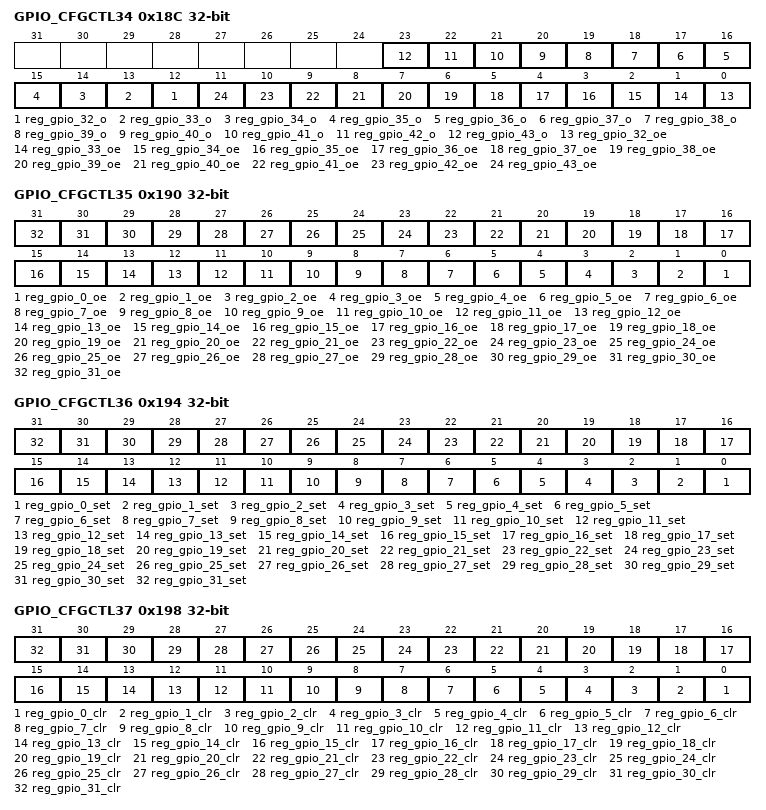
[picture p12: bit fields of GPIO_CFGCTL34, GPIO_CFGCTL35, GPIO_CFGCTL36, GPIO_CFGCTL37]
0x18C GPIO_CFGCTL34
  [n-20] reg_gpio_{n}_o (n=32..43) — Register Controlled GPIO Output Value
  [n-32] reg_gpio_{n}_oe (n=32..43) — Register Controlled GPIO Output Enable (Used when GPIO Function select to Register Control GPIO)
0x190 GPIO_CFGCTL35
  [n] reg_gpio_{n}_oe (n=0..31) — Register Controlled GPIO Output Enable (Used when GPIO Function select to Register Control GPIO)
0x194 GPIO_CFGCTL36
  [n] reg_gpio_{n}_set wo (n=0..31) — When SWGPIO @ Set/Clear Mode and reg_en_gpio_o_latch_mode =1 Set this bit will set GPIO output value to 1,when set/clr at the same time, only set take effect
0x198 GPIO_CFGCTL37
  [n] reg_gpio_{n}_clr wo (n=0..31) — When SWGPIO @ Set/Clear Mode and reg_en_gpio_o_latch_mode =1 Set this bit will clear GPIO output value to 0,when set/clr at the same time, only set take effect
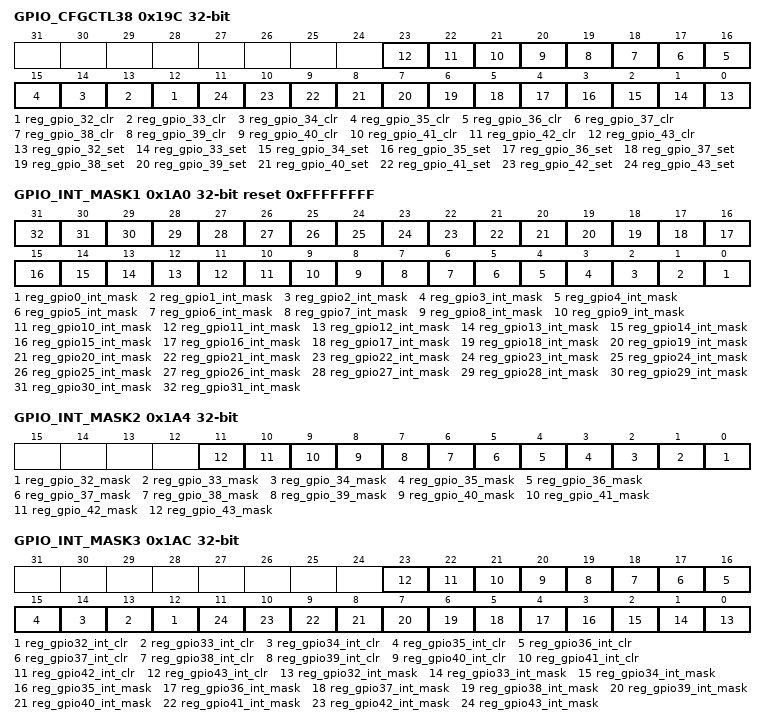
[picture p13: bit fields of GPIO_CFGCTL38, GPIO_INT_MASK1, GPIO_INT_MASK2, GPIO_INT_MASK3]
0x19C GPIO_CFGCTL38
  [n-20] reg_gpio_{n}_clr wo (n=32..43) — When SWGPIO @ Set/Clear Mode and reg_en_gpio_o_latch_mode =1 Set this bit will clear GPIO output value to 0,when set/clr at the same time, only set take effect
  [n-32] reg_gpio_{n}_set wo (n=32..43) — When SWGPIO @ Set/Clear Mode and reg_en_gpio_o_latch_mode =1 Set this bit will set GPIO output value to 1,when set/clr at the same time, only set take effect
0x1A0 GPIO_INT_MASK1 reset 0xFFFFFFFF
  [n] reg_gpio{n}_int_mask (n=0..31)
0x1A4 GPIO_INT_MASK2
  [n-32] reg_gpio_{n}_mask (n=32..43)
0x1A8 GPIO_INT_STAT1 reset not defined
  [31:0] gpio_int_stat1 ro — gpio_int_stat[31:0]
0x1AC GPIO_INT_MASK3
  [n-20] reg_gpio{n}_int_clr wo (n=32..43), [n-32] reg_gpio{n}_int_mask (n=32..43)
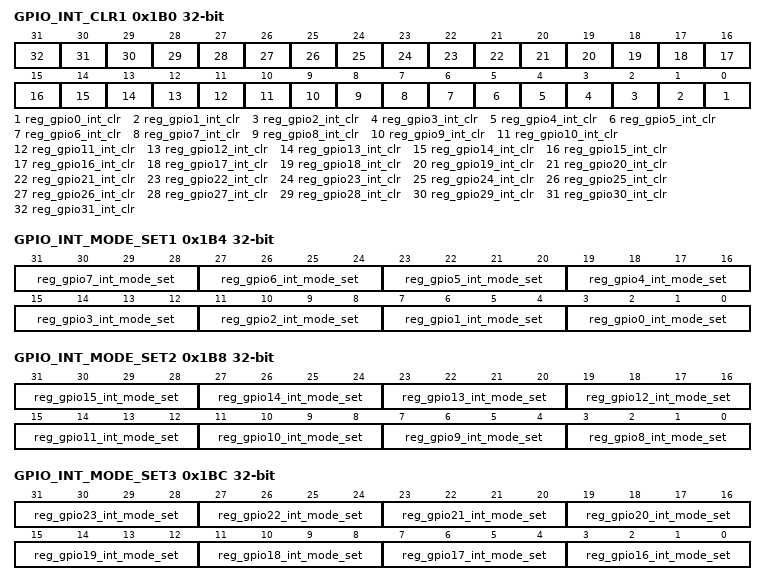
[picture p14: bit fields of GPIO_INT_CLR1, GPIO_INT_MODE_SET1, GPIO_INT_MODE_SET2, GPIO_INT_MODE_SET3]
0x1B0 GPIO_INT_CLR1
  [n] reg_gpio{n}_int_clr wo (n=0..31)
0x1B4 GPIO_INT_MODE_SET1
  [4n+3:4n] reg_gpio{n}_int_mode_set (n=0..7)
0x1B8 GPIO_INT_MODE_SET2
  [4n-29:4n-32] reg_gpio{n}_int_mode_set (n=8..15)
0x1BC GPIO_INT_MODE_SET3
  [4n-61:4n-64] reg_gpio{n}_int_mode_set (n=16..23)
0x1C0 GPIO_INT_MODE_SET4
  [4n-93:4n-96] reg_gpio{n}_int_mode_set (n=24..31)
0x1C4 GPIO_INT_MODE_SET5
  [4n-125:4n-128] reg_gpio{n}_int_mode_set (n=32..39)
0x1C8 GPIO_INT_MODE_SET6
  [4n-157:4n-160] reg_gpio{n}_int_mode_set (n=40..43)
0x224 led_driver reset 0x40
  [31] pu_leddrv, [29:28] leddrv_out_en, [6:4] leddrv_ibias, [2] led_din_polarity_sel, [1] led_din_sel, [0] led_din_reg
0x228 usb_xcvr reset 0x206333 (reset mask 0xF0FFBFFF)
  [27] usb_rcv ro — rx_d
  [26] usb_vip ro — rx_dp
  [25] usb_vim ro — rx_dm
  [24] usb_bd ro — bd output
  [23] pu_usb
  [22] usb_sus — suspend mode enable
  [21] usb_spd — full-speed/low-speed mode select
  [20] usb_enum — 0: 1.5k pull up resistor floating; 1: 1.5k pull up resistor connect to D+/D- depends on spd
  [16] usb_data_convert — 0: original vip/vim; 1: converted vip/vim
  [14] usb_oeb ro
  [13] usb_oeb_reg
  [12] usb_oeb_sel — 0: usb_oeb; 1: usb_oeb_reg
  [10:8] usb_rout_pmos
  [6:4] usb_rout_nmos
  [3] pu_usb_ldo
  [2:0] usb_ldo_vfb — ldo ref voltage
0x22C usb_xcvr_config reset 0x43432895
  [30:28] usb_slewrate_p_rise — D+ rise slew rate control
  [26:24] usb_slewrate_p_fall — D+ fall slew rate control
  [22:20] usb_slewrate_m_rise — D- rise slew rate control
  [18:16] usb_slewrate_m_fall — D- fall slew rate control
  [14:12] usb_res_pullup_tune — pull up resistor tuning
  [11] reg_usb_use_ctrl — 1: USB XCVR use on-chip usb controller ; 0: USB XCVR usb off-chip usb controller
  [10:8] usb_str_drv — driver strength
  [7] reg_usb_use_xcvr — 1: USB core use on-chip usb_xcvr; 0: USB core usb off-chip usb_xcvr
  [6:4] usb_bd_vth — bd threashold voltage
  [3:2] usb_v_hys_p — D+ input hysteresis select
  [1:0] usb_v_hys_m — D- input hysteresis select
0x300 rc32m_ctrl0 reset 0x80018 (reset mask 0xFFFFC018)
  [30] rc32m_rc32k_cal_cgen — should set this bit before 1us to enable set rc32m_cal_en or rc32k_cal_en
  [21] rc32m_pd — Power down 32m oscillator
  [20] rc32m_cal_en — Enable calibration of 32m oscillator
  [19] rc32m_ext_code_en — Allow external code in to go into the ckt
  [17] rc32m_allow_cal — Allow calibration to be performed (monitor system clock)
  [13:6] rc32m_dig_code_fr_cal ro — After calibration hold calibrated code
  [5] rc32m_cal_precharge ro — Initial a new cal
  [4:3] rc32m_cal_div — Divider for the clock step during calibration
  [2] rc32m_cal_inprogress ro — Asserts high when calibration is in progress
  [1] rc32m_rdy ro — Asserts high when 32k clock is ready upon pwrup
  [0] rc32m_cal_done ro — Asserts high when calibration is done
0x304 rc32m_ctrl1 reset 0xF006000
  [31:24] rc32m_reserved
  [17] rc32m_ext_code_sel_cgen
  [16] rc32m_ext_code_sel — should set rc32m_ext_code_sel_cgen before using rc32k_ext_code_sel
  [15:8] rc32m_code_fr_ext2
  [0] rc32m_test_en — dc test enable
0x308 rc32k_ctrl2 reset 0x21B (reset mask 0xFFFFFC18)
  [18] rc32k_allow_cal — Allow calibration to be performed (monitor system clock)
  [17:16] rc32k_dig_vref_dly — reference power up delay
  [9:6] rc32k_dig_cap_code_fr_cal ro — After calibration hold calibrated code
  [5] rc32k_dig_cal_precharge ro — Initial a new cal
  [4:3] rc32k_dig_cal_div — Divider for the clock step during calibration
  [2] rc32k_dig_cal_inprogress ro — Asserts high when calibration is in progress
  [1] rc32k_rdy ro — Asserts high when 32k clock is ready upon pwrup
  [0] rc32k_dig_cal_done ro — Asserts high when calibration is done
0x430 sdh_cfg0 reset 0x2000
  [13] reg_sdh_clk_en — SDH_CLK Enable
  [12] reg_sdh_clk_sel — 0: wifipll 96MHz 1: cpupll 100MHz
  [9:0] reg_sdh_clk_div — SDH Clock Divider
0x434 smih_0_cfg0 reset 0x120002 (reset mask 0xFC00FFFF)
  [25] st_smih_0_vol_on ro — 0-Power Off, 1-Power ON
  [24:22] st_smih_0_vol_sel ro — 111-3.3V, 110-3.0V, 101-1.8V, 100 - 1.2V others-Reserve
  [21:20] st_smih_0_drive_strength ro — 00-TypeB, 01-TypeA, 10-TypeC, 11-TypeD
  [19] st_smih_0_od_pp ro — 0-Open Drain Mode, 1-Push Pull Mode
  [18] st_smih_0_wkup_on ro — Asserted high, whenever there is a wakeup event
  [17] st_smih_0_rst_n ro — External HW Reset, Used only in MMC Mode
  [16] st_smih_0_led_on ro — Asserted high, Whenever there is a transacion on sd bus
  [1] cr_smih_0_wp — 0-Write Enabled, 1-Write Protected
  [0] cr_smih_0_cd_n — 0-Card is Present, 1-Card is not Present
0x438 smih_0_io_dly_0
  [2n+17:2n+16] cr_smih_0_d_{n}_i_dly (n=0..7) — SMIH_DATA{n}_I delay select
  [11:10] cr_smih_0_cmd_e_dly — SMIH_CMD_OE delay select
  [9:8] cr_smih_0_cmd_o_dly — SMIH_CMD_O delay select
  [7:6] cr_smih_0_cmd_i_dly — SMIH_CMD_I delay select
  [5:4] cr_smih_0_clk_o_dly — SMIH_CLK_OUT delay select
  [3:2] cr_smih_0_clk_i_dly — SMIH_CLK_IN delay select
  [1] cr_smih_0_clk_o_inv — SMIH_CLK_OUT inverse
  [0] cr_smih_0_clk_i_inv — SMIH_CLK_IN inverse
0x43C smih_0_io_dly_1
  [2n+17:2n+16] cr_smih_0_d_{n}_e_dly (n=0..7) — SMIH_DATA{n}_OE delay select
  [2n+1:2n] cr_smih_0_d_{n}_o_dly (n=0..7) — SMIH_DATA{n}_O delay select
0x50C gpadc_reg_cmd reset 0xF78
  [31] gpadc_sen_test_en — enable sensor dc test mux
  [30:28] gpadc_sen_sel — selected output current channel and measurement channel 2'h0: 1st channel 2'h1: 2nd channel 2'h2: 3rd channel 2'h3: 4th channel
  [27] gpadc_chip_sen_pu — enable chip sensor test 1'b0: disable 1'b1: enable
  [23] gpadc_micboost_32db_en — micboost 32db enable 1'b0: 16dB 1'b1: 32dB
  [22:21] gpadc_mic_pga2_gain — mic_pga2_gain 2'h0: 0dB 2'h1: 6dB 2'h2: -6dB 2'h3: 12dB
  [20] gpadc_mic1_diff — mic1 diff enable 1'b0: single 1'b1: diff
  [19] gpadc_mic2_diff — mic2 diff enable 1'b0: single 1'b1: diff
  [18] gpadc_dwa_en — dwa enable 1'b0: dwa disable 1'b1: dwa enable
  [17] gpadc_rcal_en — rcal enable 1'b0: rcal disable 1'b1: rcal enable
  [16] gpadc_byp_micboost — micboost amp bypass 1'b0: not bypass 1'b1: bypass
  [15] gpadc_micpga_en — micpga enable 1'b0: micpga disable 1'b1: miapga enable
  [14] gpadc_micbias_en — enable micbias 1'b0: micbias power down 1'b1: miabias power on
  [13] gpadc_neg_gnd — set negative input of adc to ground 1'b0: disable 1'b1: enable
  [12:8] gpadc_pos_sel — select adc positive input in none-scan mode 4'b0000 gpio0 4'b0001 gpio1 4'b0010 gpio2 4'b0011 gpio3 4'b0100 gpio4 4'b0101 gpio5 4'b0110 gpio6 4'b0111 gpio7 4'b1000 daca 4'b1001 dacb 4'b1010 vbat 4'b1011 tsen 4'b1100 vref 4'b1101 gnd 4'b1111 disable
  [7:3] gpadc_neg_sel — select adc negative input in none-scan mode 4'b0000 gpio0 4'b0001 gpio1 4'b0010 gpio2 4'b0011 gpio3 4'b0100 gpio4 4'b0101 gpio5 4'b0110 gpio6 4'b0111 gpio7 4'b1000 daca 4'b1001 dacb 4'b1010 vbat 4'b1011 tsen 4'b1100 vref 4'b1101 gnd 4'b1111 disable
  [2] gpadc_soft_rst — user reset the whole block 1'h0: not reset 1'h1: reset
  [1] gpadc_conv_start — 1'h0: stop converation 1'h1: start converation
  [0] gpadc_global_en — 1'h0: disable ADC 1'h1: enable ADC
0x510 gpadc_reg_config1 reset 0xC0002
  [30:29] gpadc_v18_sel — internal vdd18 select
  [28:27] gpadc_v11_sel — internal vdd11 select
  [26] gpadc_dither_en — Dither compensation enable
  [25] gpadc_scan_en — select scan mode enable: 0: select gpadc_pos/neg_sel;1: select : select gpadc_scan_pos_x and gpadc_scan_neg_x
  [24:21] gpadc_scan_length — select scan mode length 4'b0000 : select gpadc_scan_pos_0 and gpadc_scan_neg_0 4'b0001 : select gpadc_scan_pos_1 and gpadc_scan_neg_1 4'b0010 : select gpadc_scan_pos_2 and gpadc_scan_neg_2 4'b0011 : select gpadc_scan_pos_3 and gpadc_scan_neg_3 4'b0100 : select gpadc_scan_pos_4 and gpadc_scan_neg_4 4'b0101 : select gpadc_scan_pos_5 and gpadc_scan_neg_5 4'b0110 : select gpadc_scan_pos_6 and gpadc_scan_neg_6 4'b0111 : select gpadc_scan_pos_7 and gpadc_scan_neg_7 4'b1000 : select gpadc_scan_pos_8 and gpadc_scan_neg_8 4'b1001 : select gpadc_scan_pos_9 and gpadc_scan_neg_9 4'b1010 : select gpadc_scan_pos_10 and gpadc_scan_neg_10 4'b1011 : select gpadc_scan_pos_11 and gpadc_scan_neg_11
  [20:18] gpadc_clk_div_ratio — analog 32M clock division ratio 3'b000: div=1 3'b001: div=4 3'b010: div=8 3'b011: div=12 3'b100: div=16 3'b101: div=20 3'b110: div=24 3'b111: div=32
  [17] gpadc_clk_ana_inv — analog clock 2M inverted
  [16] gpadc_clk_ana_dly_en — analog clock 2M delay enable
  [15:12] gpadc_clk_ana_dly — analog clock 2M delay cycle count
  [11] gpadc_pwm_trg_en — Enable signal for PWM to trigger ADC sampling
  [10] gpadc_lowv_det_en
  [9] gpadc_vcm_hyst_sel
  [8] gpadc_vcm_sel_en
  [4:2] gpadc_res_sel — adc resolution/over-sample rate select 3'b000 12bit 2MS/s, OSR=1 3'b001 14bit 125kS/s, OSR=16 3'b010 14bit 31.25kS/s, OSR=64 3'b011 16bit 15.625KS/s, OSR=128 (voice mode16KS/s) 3'b100 16bit 7.8125KS/s, OSR=256 (voice mode 8KS/s)
  [1] gpadc_cont_conv_en — To enable continuous conversion 1'h0: one shot conversion 1'h1: continuous conversion
0x514 gpadc_reg_config2 reset 0x19100
  [31] gpadc_tsvbe_low — tsen diode current
  [30:28] gpadc_dly_sel — adc conversion speed
  [27:25] gpadc_pga1_gain — 3'h0: disable 3'h1: gain=1 3'h2: gain=2 3'h3: gain=4 3'h4: gain=8 3'h5: gain=16 3'h6: gain=32 3'h7: gain=32
  [24:22] gpadc_pga2_gain — 3'h0: disable 3'h1: gain=1 3'h2: gain=2 3'h3: gain=4 3'h4: gain=8 3'h5: gain=16 3'h6: gain=32 3'h7: gain=32
  [21:19] gpadc_test_sel — select test point 0~7
  [18] gpadc_test_en — Analog test enable.
  [17] gpadc_bias_sel — adc analog portion low power mode select 1'h0: Full biasing current 1'h1: Half biasing current
  [16:15] gpadc_chop_mode — 2'b11 all off 2'b11 Vref AZ on 2'b11 Vref AZ and PGA chop on 2'b11 Vref AZ and PGA chop+RPC on
  [14] gpadc_pga_vcmi_en — enable pga input vcm bias
  [13] gpadc_pga_en — 1'h0: disable PGA 1'h1 enable PGA
  [12:9] gpadc_pga_os_cal — pga offset calibration
  [8:7] gpadc_pga_vcm — Audio PGA output common mode control 2'b00: cm=1V 2'b11: cm=1.2V 2'b11: cm=1.4V 2'b11: cm=1.6V
  [6] gpadc_ts_en — 1'h0: disable temperature sensor 1'h1: enable temperature sensor
  [5] gpadc_tsext_sel — 1'h0: internal diode mode 1'h1: external diode mode
  [4] gpadc_vbat_en — 1'h0: disable VBAT sensor 1'h1 enable VBAT sensor
  [3] gpadc_vref_sel — ADC reference select 1'h0 3.3V 1'h1 1.8V
  [2] gpadc_diff_mode — 1'h0 single-ended 1'h1 differential
0x518 gpadc_reg_scn_pos1 reset 0x1EF7BDEF — adc converation sequence 1
  [5n+4:5n] gpadc_scan_pos_{n} (n=0..5) — definition is the same as adc_reg_cmd.adc_pos_sel
0x51C gpadc_reg_scn_pos2 reset 0x1EF7BDEF — adc converation sequence 2
  [5n-26:5n-30] gpadc_scan_pos_{n} (n=6..11) — definition is the same as adc_reg_cmd.adc_pos_sel
0x520 gpadc_reg_scn_neg1 reset 0x1EF7BDEF — adc converation sequence 3
  [5n+4:5n] gpadc_scan_neg_{n} (n=0..5) — definition is the same as adc_reg_cmd.adc_neg_sel
0x524 gpadc_reg_scn_neg2 reset 0x1EF7BDEF — adc converation sequence 4
  [5n-26:5n-30] gpadc_scan_neg_{n} (n=6..11) — definition is the same as adc_reg_cmd.adc_neg_sel
0x528 gpadc_reg_status (reset mask 0xFFFFFFFE)
  [31:16] gpadc_reserved
  [0] gpadc_data_rdy ro — ADC final conversion data ready
0x52C gpadc_reg_isr (reset mask 0xFFFFFFFC)
  [9] gpadc_pos_satur_mask — write 1 mask
  [8] gpadc_neg_satur_mask — write 1 mask
  [5] gpadc_pos_satur_clr — Write 1 to clear flag
  [4] gpadc_neg_satur_clr — Write 1 to clear flag
  [1] gpadc_pos_satur ro — ADC data positive side saturation interrupt flag
  [0] gpadc_neg_satur ro — ADC data negative side saturation interrupt flag
0x530 gpadc_reg_result reset 0x1EF0000 (reset mask 0xFC000000)
  [25:0] gpadc_data_out ro — ADC finial conversion result data, after calibration and signed/unsigned process
0x534 gpadc_reg_raw_result (reset mask 0xFFFFF000)
  [11:0] gpadc_raw_data ro — ADC Raw data
0x538 gpadc_reg_define
  [15:0] gpadc_os_cal_data — User defined or self calculated offset data 16-bit signed
0x608 gpdac_ctrl reset 0xF000003
  [31:24] gpdac_reserved
  [11:9] gpdac_test_sel — select test point 0~7
  [8] gpdac_ref_sel — Reference select 1'h0 Internal reference 1'h1 External reference
  [7] gpdac_test_en — Test enable 1'h0 analog test disabled (ATEST is set in Hi-Z state) 1'h1 analog test point enabled to ATEST
  [1] gpdacb_rstn_ana — Soft reset for DAC channel B, active low
  [0] gpdaca_rstn_ana — Soft reset for DAC channel A, active low
0x60C gpdac_actrl reset 0xC0000
  [22:20] gpdac_a_outmux
  [19:18] gpdac_a_rng — Output voltage range control with internal/external reference
  [1] gpdac_ioa_en — Channel A conversion output to pad enable 1'h0 Disable channel A conversion result to GPIO 1'h1 Enable channel A conversion result to GPIO
  [0] gpdac_a_en — Channel A enable/disable signal 1'h0 Disable channel A conversion. 1'h1 Enable channel A conversion
0x610 gpdac_bctrl reset 0xC0000
  [22:20] gpdac_b_outmux
  [19:18] gpdac_b_rng
  [1] gpdac_iob_en — channel B conversion output to pad enable 1'h0 Disable channel B conversion result to GPIO 1'h1 Enable channel B conversion result to GPIO
  [0] gpdac_b_en — channel B enable/disable signal 1'h0 Disable channel B conversion. 1'h1 Enable channel B conversion
0x614 gpdac_data
  [25:16] gpdac_a_data — Channel A Data input
  [9:0] gpdac_b_data — Channel B Data input
0xF00 tzc_glb_ctrl_0 (reset mask 0x9FF8EFC)
  [31] tzc_glb_clk_lock ro, [30] tzc_glb_mbist_lock ro, [29] tzc_glb_dbg_lock ro, [28] tzc_glb_bmx_lock ro, [26] tzc_glb_sram_lock ro, [25] tzc_glb_misc_lock ro, [14] tzc_glb_ctrl_sys_reset_lock ro, [13] tzc_glb_ctrl_cpu_reset_lock ro, [12] tzc_glb_ctrl_pwron_rst_lock ro, [8] tzc_glb_swrst_s30_lock ro, [1] tzc_glb_swrst_s01_lock ro, [0] tzc_glb_swrst_s00_lock ro
0xF04 tzc_glb_ctrl_1 reset not defined
  [31] tzc_glb_swrst_s1f_lock ro, [30] tzc_glb_swrst_s1e_lock ro, [29] tzc_glb_swrst_s1d_lock ro, [28] tzc_glb_swrst_s1c_lock ro, [27] tzc_glb_swrst_s1b_lock ro, [26] tzc_glb_swrst_s1a_lock ro, [n+6] tzc_glb_swrst_s{n}_lock ro (n=10..19), [15] tzc_glb_swrst_s2f_lock ro, [14] tzc_glb_swrst_s2e_lock ro, [13] tzc_glb_swrst_s2d_lock ro, [12] tzc_glb_swrst_s2c_lock ro, [11] tzc_glb_swrst_s2b_lock ro, [10] tzc_glb_swrst_s2a_lock ro, [n-20] tzc_glb_swrst_s{n}_lock ro (n=20..29)
0xF08 tzc_glb_ctrl_2 reset not defined
  [n] tzc_glb_gpio_{n}_lock ro (n=0..31)
0xF0C tzc_glb_ctrl_3 (reset mask 0xFFC00000)
  [n-32] tzc_glb_gpio_{n}_lock ro (n=32..53)
